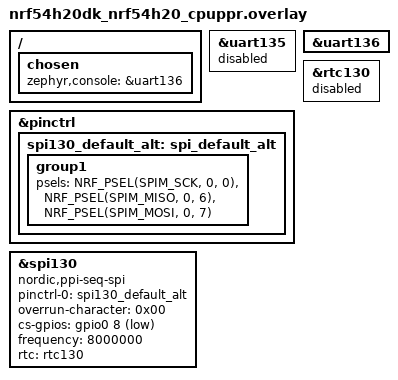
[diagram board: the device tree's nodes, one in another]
/*
 * Copyright (c) 2026 Nordic Semiconductor ASA
 *
 * SPDX-License-Identifier: LicenseRef-Nordic-5-Clause
 */

/ {
	chosen {
		zephyr,console = &uart136;
	};
};

&uart135 {
	status = "disabled";
};

&uart136 {
	status = "okay";
};

&pinctrl {
	spi130_default_alt: spi_default_alt {
		group1 {
			psels = <NRF_PSEL(SPIM_SCK, 0, 0)>,
				<NRF_PSEL(SPIM_MISO, 0, 6)>,
				<NRF_PSEL(SPIM_MOSI, 0, 7)>;
		};
	};
};

&rtc130 {
	status = "reserved";
};

sample_spi: &spi130 {
	compatible = "nordic,ppi-seq-spi";
	status = "okay";
	pinctrl-0 = <&spi130_default_alt>;
	pinctrl-names = "default";
	overrun-character = <0x00>;
	cs-gpios = <&gpio0 8 GPIO_ACTIVE_LOW>;
	frequency = <8000000>;
	rtc = <&rtc130>;
};
